VERSION ""

NS_ :

BS_:

BU_: DBG DRIVER IO MOTOR SENSOR

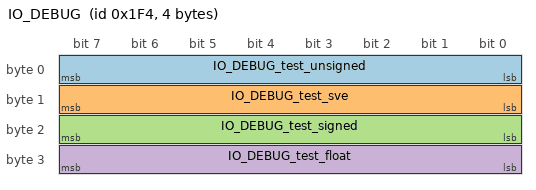
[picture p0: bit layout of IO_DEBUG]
BO_ 500 IO_DEBUG: 4 IO
 SG_ IO_DEBUG_test_unsigned : 0|8@1+ (1,0) [0|255] "" DBG
 SG_ IO_DEBUG_test_sve : 8|8@1+ (1,0) [0|255] "" DBG
 SG_ IO_DEBUG_test_signed : 16|8@1- (1,0) [-128|127] "" DBG
 SG_ IO_DEBUG_test_float : 24|8@1+ (0.5,0) [0|127.5] "" DBG

BO_ 400 MOTOR_STATUS: 3 MOTOR
 SG_ MOTOR_STATUS_wheel_error : 0|1@1+ (1,0) [0|1] "" DRIVER,IO
 SG_ MOTOR_STATUS_speed_kph : 8|16@1+ (0.001,0) [0|65] "kph" DRIVER,IO

CM_ BU_ DRIVER "The driver controller driving the car";
CM_ BU_ MOTOR "The motor controller of the car";
CM_ BU_ SENSOR "The sensor controller of the car";
CM_ BO_ 100 "Sync message used to synchronize the controllers";

VAL_ 500 IO_DEBUG_test_sve 2 "IO_DEBUG_test_sve_two" 1 "IO_DEBUG_test_sve_one" ;
